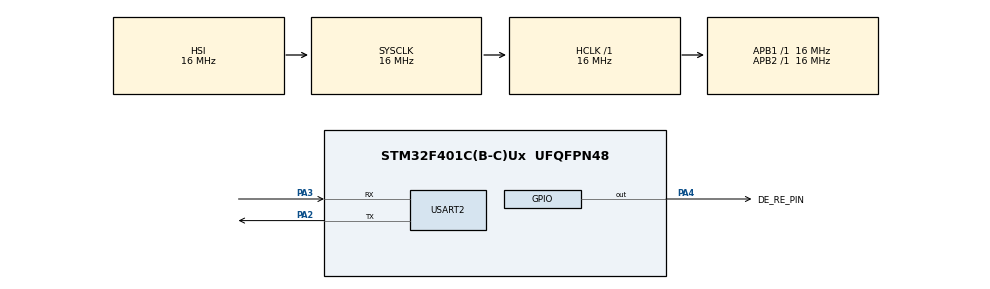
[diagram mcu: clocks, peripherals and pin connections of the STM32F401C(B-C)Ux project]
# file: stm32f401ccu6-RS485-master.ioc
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Mcu.Family=STM32F4
Mcu.Name=STM32F401C(B-C)Ux
Mcu.Package=UFQFPN48
NVIC.PriorityGroup=NVIC_PRIORITYGROUP_4
NVIC.USART2_IRQn=true\:0\:0\:false\:false\:true\:true\:true\:true
PA13.Mode=Serial_Wire
PA13.Signal=SYS_JTMS-SWDIO
PA14.Mode=Serial_Wire
PA14.Signal=SYS_JTCK-SWCLK
PA2.Mode=Asynchronous
PA2.Signal=USART2_TX
PA3.Mode=Asynchronous
PA3.Signal=USART2_RX
PA4.GPIO_Label=DE_RE_PIN
PA4.Signal=GPIO_Output
PH0\ -\ OSC_IN.Mode=HSE-External-Oscillator
PH0\ -\ OSC_IN.Signal=RCC_OSC_IN
PH1\ -\ OSC_OUT.Mode=HSE-External-Oscillator
PH1\ -\ OSC_OUT.Signal=RCC_OSC_OUT
ProjectManager.HeapSize=0x200
ProjectManager.StackSize=0x400
ProjectManager.TargetToolchain=STM32CubeIDE
RCC.AHBFreq_Value=16000000
RCC.APB1Freq_Value=16000000
RCC.APB2Freq_Value=16000000
RCC.CortexFreq_Value=16000000
RCC.HSE_VALUE=25000000
RCC.HSI_VALUE=16000000
RCC.LSE_VALUE=32768
RCC.SYSCLKFreq_VALUE=16000000
RCC.VCOOutputFreq_Value=192000000
USART2.VirtualMode=VM_ASYNC
board=custom

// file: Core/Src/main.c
/* USER CODE BEGIN Header */
/**
  ******************************************************************************
  * @file           : main.c
  * @brief          : Main program body
  ******************************************************************************
  * @attention
  *
  * Copyright (c) 2025 STMicroelectronics.
  * All rights reserved.
  *
  * This software is licensed under terms that can be found in the LICENSE file
  * in the root directory of this software component.
  * If no LICENSE file comes with this software, it is provided AS-IS.
  *
  * THIS IS THE MODBUS MASTER DEVICE
  ******************************************************************************
  */
/* USER CODE END Header */
#include "main.h"

/* USER CODE BEGIN Includes */
#include <stdio.h>
#include <string.h>

/* USER CODE END Includes */

UART_HandleTypeDef huart2;

void SystemClock_Config(void);
static void MX_GPIO_Init(void);
static void MX_USART2_UART_Init(void);

/* USER CODE BEGIN PFP */

uint16_t calculate_CRC(const uint8_t* buf, uint16_t len);
void master_read_coils_request(uint8_t slave_addr, uint16_t start_addr, uint16_t quantity);
void send_data(uint8_t*);

/* USER CODE END PFP */

/* USER CODE BEGIN 0 */
#define MSG_LEN 40

char tx_data[MSG_LEN];
uint8_t rx_data[MSG_LEN];
int indx = 0;

/* USER CODE END 0 */

int main(void)
{

  /* MCU Configuration--------------------------------------------------------*/

  /* Reset of all peripherals, Initializes the Flash interface and the Systick. */
  HAL_Init();

  /* Configure the system clock */
  SystemClock_Config();

  /* Initialize all configured peripherals */
  MX_GPIO_Init();
  MX_USART2_UART_Init();
  /* USER CODE BEGIN 2 */

  // receive up to 	idle LINE
  HAL_UARTEx_ReceiveToIdle_IT(&huart2, rx_data, MSG_LEN);

  /* USER CODE END 2 */

  /* Infinite loop */
  while (1)
  {

    /* USER CODE BEGIN 3 */

	//PREPARE THE MESSAGE
	sprintf(tx_data, "MSG FROM MASTER, %d", indx++);
	send_data(tx_data);

//	master_read_coils_request(0x01, 0x0000, 8);
	HAL_Delay(1000);
  }
  /* USER CODE END 3 */
}

void SystemClock_Config(void)
{
  RCC_OscInitTypeDef RCC_OscInitStruct = {0};
  RCC_ClkInitTypeDef RCC_ClkInitStruct = {0};

  /** Configure the main internal regulator output voltage
  */
  __HAL_RCC_PWR_CLK_ENABLE();
  __HAL_PWR_VOLTAGESCALING_CONFIG(PWR_REGULATOR_VOLTAGE_SCALE2);

  /** Initializes the RCC Oscillators according to the specified parameters
  * in the RCC_OscInitTypeDef structure.
  */
  RCC_OscInitStruct.OscillatorType = RCC_OSCILLATORTYPE_HSI;
  RCC_OscInitStruct.HSIState = RCC_HSI_ON;
  RCC_OscInitStruct.HSICalibrationValue = RCC_HSICALIBRATION_DEFAULT;
  RCC_OscInitStruct.PLL.PLLState = RCC_PLL_NONE;
  if (HAL_RCC_OscConfig(&RCC_OscInitStruct) != HAL_OK)
  {
    Error_Handler();
  }

  /** Initializes the CPU, AHB and APB buses clocks
  */
  RCC_ClkInitStruct.ClockType = RCC_CLOCKTYPE_HCLK|RCC_CLOCKTYPE_SYSCLK
                              |RCC_CLOCKTYPE_PCLK1|RCC_CLOCKTYPE_PCLK2;
  RCC_ClkInitStruct.SYSCLKSource = RCC_SYSCLKSOURCE_HSI;
  RCC_ClkInitStruct.AHBCLKDivider = RCC_SYSCLK_DIV1;
  RCC_ClkInitStruct.APB1CLKDivider = RCC_HCLK_DIV1;
  RCC_ClkInitStruct.APB2CLKDivider = RCC_HCLK_DIV1;

  if (HAL_RCC_ClockConfig(&RCC_ClkInitStruct, FLASH_LATENCY_0) != HAL_OK)
  {
    Error_Handler();
  }
}

static void MX_USART2_UART_Init(void)
{

  huart2.Instance = USART2;
  huart2.Init.BaudRate = 115200;
  huart2.Init.WordLength = UART_WORDLENGTH_8B;
  huart2.Init.StopBits = UART_STOPBITS_1;
  huart2.Init.Parity = UART_PARITY_NONE;
  huart2.Init.Mode = UART_MODE_TX_RX;
  huart2.Init.HwFlowCtl = UART_HWCONTROL_NONE;
  huart2.Init.OverSampling = UART_OVERSAMPLING_16;
  if (HAL_UART_Init(&huart2) != HAL_OK)
  {
    Error_Handler();
  }

}

static void MX_GPIO_Init(void)
{
  GPIO_InitTypeDef GPIO_InitStruct = {0};

  /* GPIO Ports Clock Enable */
  __HAL_RCC_GPIOH_CLK_ENABLE();
  __HAL_RCC_GPIOA_CLK_ENABLE();

  /*Configure GPIO pin Output Level */
  HAL_GPIO_WritePin(DE_RE_PIN_GPIO_Port, DE_RE_PIN_Pin, GPIO_PIN_RESET);

  /*Configure GPIO pin : DE_RE_PIN_Pin */
  GPIO_InitStruct.Pin = DE_RE_PIN_Pin;
  GPIO_InitStruct.Mode = GPIO_MODE_OUTPUT_PP;
  GPIO_InitStruct.Pull = GPIO_NOPULL;
  GPIO_InitStruct.Speed = GPIO_SPEED_FREQ_LOW;
  HAL_GPIO_Init(DE_RE_PIN_GPIO_Port, &GPIO_InitStruct);

}

/* USER CODE BEGIN 4 */
void HAL_UARTEx_RxEventCallback(UART_HandleTypeDef *huart, uint16_t Size) {
	// restart the interrupt because HAL disables the interrupt
	// after each call
	HAL_UARTEx_ReceiveToIdle_IT(&huart2, rx_data, MSG_LEN);
}

uint16_t calculate_CRC(const uint8_t* buf, uint16_t len) {
	uint16_t crc = 0xFFFF;
	for(uint16_t pos = 0; pos < len; pos++) {
		crc ^= (uint16_t)buf[pos];

		for(int i = 0; i < 8; i++) {
			if(crc & 0x0001) crc = (crc>>1) ^ 0xA001;
			else crc >>= 1;
		}
	}

	return crc;
}

void master_read_coils_request(uint8_t slave_addr, uint16_t start_addr, uint16_t quantity) {
	uint8_t tx_frame[8];
	tx_frame[0] = slave_addr;
	tx_frame[1] = 0x01;
	tx_frame[2] = (start_addr >> 8) & 0xFF;
	tx_frame[3] = (start_addr) & 0xFF;
	tx_frame[4] = (quantity >> 8) & 0xFF;
	tx_frame[5] = (quantity) & 0xFF;

	/* calculate CRC */
	uint16_t crc = calculate_CRC(tx_frame, 6);

	tx_frame[6] = crc & 0xFF;		 // CRC LOW byte
	tx_frame[7] = (crc >> 8) & 0xFF; // CRC HIGH byte

	//send_data(tx_frame);
}

void send_data(uint8_t* data) {
	 // continuously send a string to slave after every second
	 // and wait for received response
	HAL_GPIO_WritePin(DE_RE_PIN_GPIO_Port, DE_RE_PIN_Pin, GPIO_PIN_SET); // enable transmit
	HAL_UART_Transmit(&huart2, data, strlen(data), 1000);
	HAL_GPIO_WritePin(DE_RE_PIN_GPIO_Port, DE_RE_PIN_Pin, GPIO_PIN_RESET); // enable receive
}

/* USER CODE END 4 */

void Error_Handler(void)
{
  __disable_irq();
  while (1)
  {
  }
}
